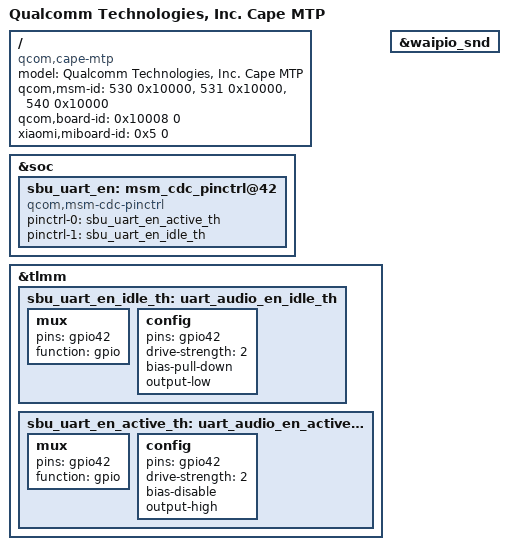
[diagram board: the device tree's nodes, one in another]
/dts-v1/;
/plugin/;

#include "xiaomi-sm8450-common.dtsi"

 / {
	model = "Qualcomm Technologies, Inc. Cape MTP";
	compatible = "qcom,cape-mtp", "qcom,cape", "qcom,mtp";
	qcom,msm-id = <530 0x10000>, <531 0x10000>, <540 0x10000>;
	qcom,board-id = <0x10008 0>;
	xiaomi,miboard-id = <0x5 0>;
};

&soc {
	sbu_uart_en: msm_cdc_pinctrl@42 {
		compatible = "qcom,msm-cdc-pinctrl";
		pinctrl-names = "aud_active", "aud_sleep";
		pinctrl-0 = <&sbu_uart_en_active_th>;
		pinctrl-1 = <&sbu_uart_en_idle_th>;
		#gpio-cells = <0>;
	};
};

&tlmm {
	sbu_uart_en_idle_th: uart_audio_en_idle_th {
		mux {
			pins = "gpio42";
			function = "gpio";
		};
		config {
			pins = "gpio42";
			drive-strength = <2>;
			bias-pull-down;
			output-low;
		};
	};

	sbu_uart_en_active_th: uart_audio_en_active_th {
		mux {
			pins = "gpio42";
			function = "gpio";
		};
		config {
			pins = "gpio42";
			drive-strength = <2>;
			bias-disable;
			output-high;
		};
	};
};

&waipio_snd {
	/delete-property/qcom,uart-audio-sw-gpio;
};
